# M3HQ register map
File version: 0.1
Registers are 32-bit, read-write, reset 0x0 unless marked. A register's access mark holds for its fields unless they carry their own. Offsets are from the block's base; [hi:lo] are bit positions; {n}, {i} and the like mark numbered series.

## PV
Base 0x400C1100
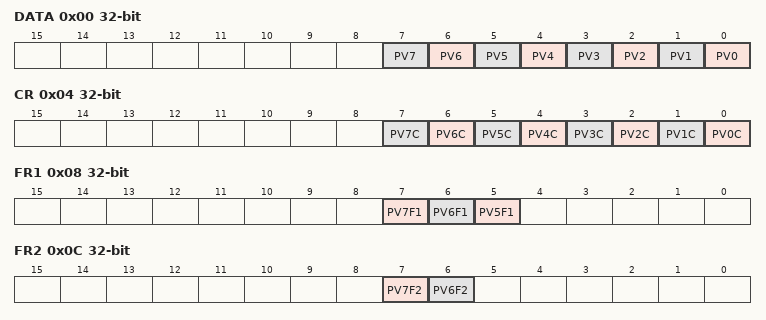
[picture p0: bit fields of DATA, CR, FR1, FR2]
0x00 DATA — PV Data Register
  [n] PV{n} (n=0..7)
0x04 CR — PV Control Register
  [n] PV{n}C (n=0..7)
0x08 FR1 — PV Function Register 1
  [7] PV7F1, [6] PV6F1, [5] PV5F1
0x0C FR2 — PV Function Register 2
  [7] PV7F2, [6] PV6F2
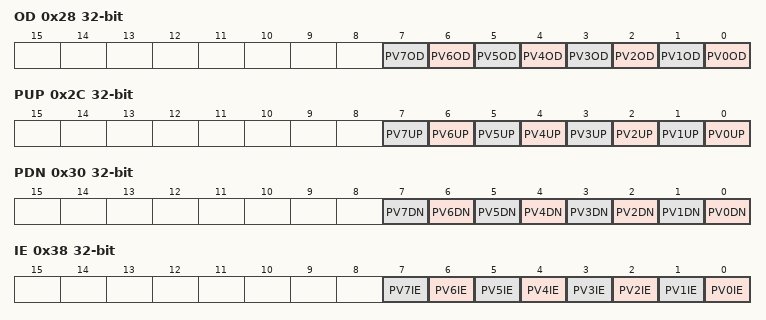
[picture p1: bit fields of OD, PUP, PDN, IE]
0x28 OD — PV Open Drain Control Register
  [n] PV{n}OD (n=0..7)
0x2C PUP — PV Pull-up Control Register
  [n] PV{n}UP (n=0..7)
0x30 PDN — PV Pull-Down Control Register
  [n] PV{n}DN (n=0..7)
0x38 IE — PV Input Enable Control Register
  [n] PV{n}IE (n=0..7)

## RTC
Base 0x400CC000
0x00 SECR 8-bit (reset mask 0x80) — RTC Sec setting register
  [6:0] SE
0x01 MINR 8-bit (reset mask 0x80) — RTC Min settging register
  [6:0] MI
0x02 HOURR 8-bit (reset mask 0xC0) — RTC Hour setting register
  [5:0] HO
0x04 DAYR 8-bit (reset mask 0xF8) — RTC Day setting register
  [2:0] WE
0x05 DATER 8-bit (reset mask 0xC0) — RTC Date setting register
  [5:0] DA
0x06 MONTHR_A 8-bit (reset mask 0xE0) — RTC Month settging register PAGE0
  [4:0] MO
0x06 MONTHR_B 8-bit (reset mask 0xFE) (RTC_MONTHR view) — RTC 24 hours _ 12 hours clock select register PAGE1
  [0] MO0
0x07 YEARR_A 8-bit reset not defined — RTC Year setting register PAGE0
  [7:0] YE
0x07 YEARR_B 8-bit (reset mask 0xFC) (RTC_YEARR view) — RTC Leap year register PAGE1
  [1:0] LEAP
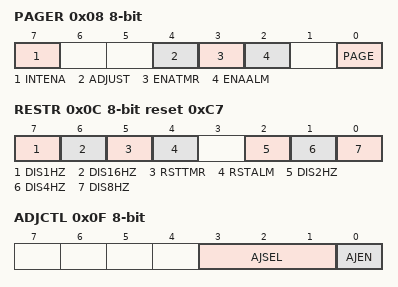
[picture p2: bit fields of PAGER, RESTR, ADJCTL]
0x08 PAGER 8-bit (reset mask 0xF3) — RTC Page register
  [7] INTENA, [4] ADJUST, [3] ENATMR, [2] ENAALM, [0] PAGE
0x0C RESTR 8-bit reset 0xC7 — RTC Reset register
  [7] DIS1HZ, [6] DIS16HZ, [5] RSTTMR, [4] RSTALM, [2] DIS2HZ, [1] DIS4HZ, [0] DIS8HZ
0x0E PROTECT 8-bit reset 0xC1 — RTC protect register
0x0F ADJCTL 8-bit (reset mask 0xF0) — RTC clock adjust control register
  [3:1] AJSEL, [0] AJEN
0x10 ADJDAT 8-bit reset not defined — RTC clock adjust data register
0x11 ADJSIGN 8-bit (reset mask 0xFE) — RTC clock adjust sign register
  [0] ADJSIGN

## RMC
Base 0x400E7000
0x00 EN — RMC Enable Register
  [0] RMCEN
0x04 REN — RMC Receive Enable Register
  [0] RMCREN
0x08 RBUF1 ro — RMC Receive Data Buffer Register 1
  [31:0] RMCRBUF
0x0C RBUF2 ro — RMC Receive Data Buffer Register 2
  [31:0] RMCRBUF
0x10 RBUF3 ro — RMC Receive Data Buffer Register 3
  [7:0] RMCRBUF
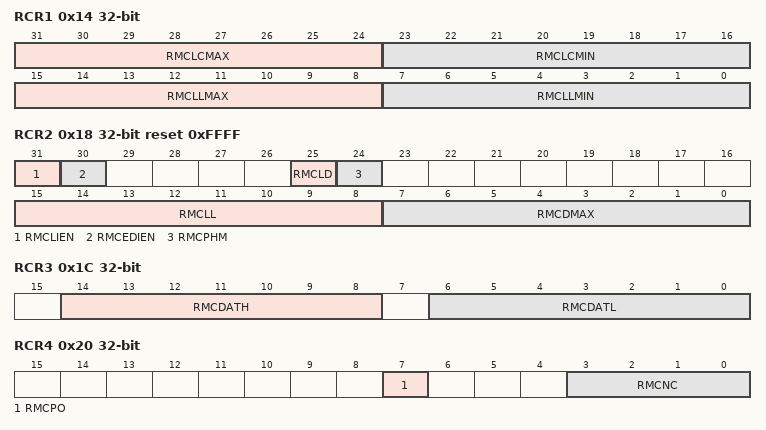
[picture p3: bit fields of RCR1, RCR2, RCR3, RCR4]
0x14 RCR1 — RMC Receive Control Register 1
  [31:24] RMCLCMAX, [23:16] RMCLCMIN, [15:8] RMCLLMAX, [7:0] RMCLLMIN
0x18 RCR2 reset 0xFFFF — RMC Receive Control Register 2
  [31] RMCLIEN, [30] RMCEDIEN, [25] RMCLD, [24] RMCPHM, [15:8] RMCLL, [7:0] RMCDMAX
0x1C RCR3 — RMC Receive Control Register 3
  [14:8] RMCDATH, [6:0] RMCDATL
0x20 RCR4 — RMC Receive Control Register 4
  [7] RMCPO, [3:0] RMCNC
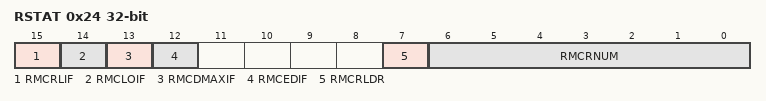
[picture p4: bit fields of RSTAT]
0x24 RSTAT ro — RMC Receive Status Register
  [15] RMCRLIF, [14] RMCLOIF, [13] RMCDMAXIF, [12] RMCEDIF, [7] RMCRLDR, [6:0] RMCRNUM
{0x24+4i} END{i} (i=1..3) — RMC Receive End Bit Number Register {i}
  [6:0] RMCEND{i}
0x34 FSSEL — RMC Frequency Selection Register
  [0] RMCCLK

## OFD
Base 0x400F1000
0x00 CR1 reset 0x6 — OFD Control Register 1
  [7:0] OFDWEN
0x04 CR2 — OFD Control Register 2
  [7:0] OFDEN
0x08 MN0 — OFD Lower Detection Frequency Setting Register0
  [11:0] OFDMN0
0x0C MN1 — OFD Lower Detection Frequency Setting Register1
  [11:0] OFDMN1
0x10 MX0 — OFD Higher Detection Frequency Setting Register0
  [11:0] OFDMX0
0x14 MX1 — OFD Higher Detection Frequency Setting Register1
  [11:0] OFDMX1
0x18 RST reset 0x1 — OFD Reset Enable Control Register
  [0] OFDRSTEN
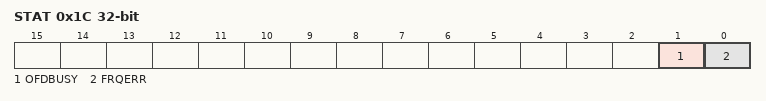
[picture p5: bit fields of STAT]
0x1C STAT ro — OFD Status Register
  [1] OFDBUSY, [0] FRQERR
0x20 MON reset 0x1 — OFD External high frequency oscillaion clock monitor register
  [0] OFDMON

## CG
Base 0x400F3000
0x00 PROTECT reset 0xC1 — CG Protect Register
  [7:0] PROTECT
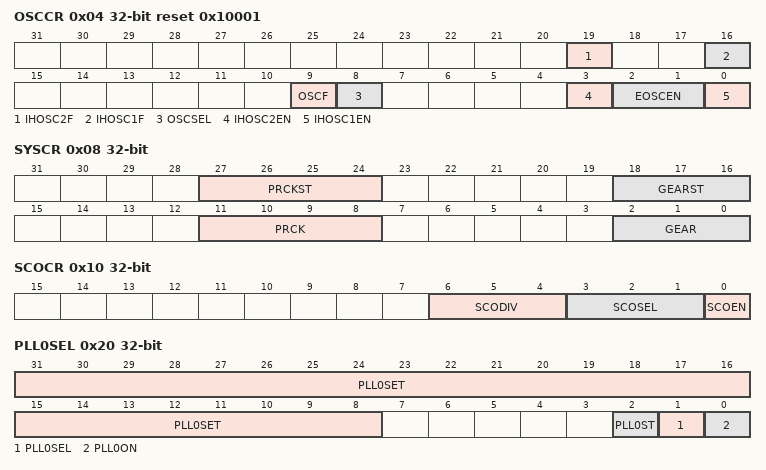
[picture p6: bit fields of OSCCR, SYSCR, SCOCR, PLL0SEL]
0x04 OSCCR reset 0x10001 — CG Oscillation Control Register
  [19] IHOSC2F ro, [16] IHOSC1F ro, [9] OSCF ro, [8] OSCSEL, [3] IHOSC2EN, [2:1] EOSCEN, [0] IHOSC1EN
0x08 SYSCR — CG System clock control register
  [27:24] PRCKST ro, [18:16] GEARST ro, [11:8] PRCK, [2:0] GEAR
0x0C STBYCR — CG Standby Control Register
  [1:0] STBY
0x10 SCOCR — CG SCOUT Control Register
  [6:4] SCODIV, [3:1] SCOSEL, [0] SCOEN
0x20 PLL0SEL — CG PLL select register for fsys
  [31:8] PLL0SET, [2] PLL0ST ro, [1] PLL0SEL, [0] PLL0ON
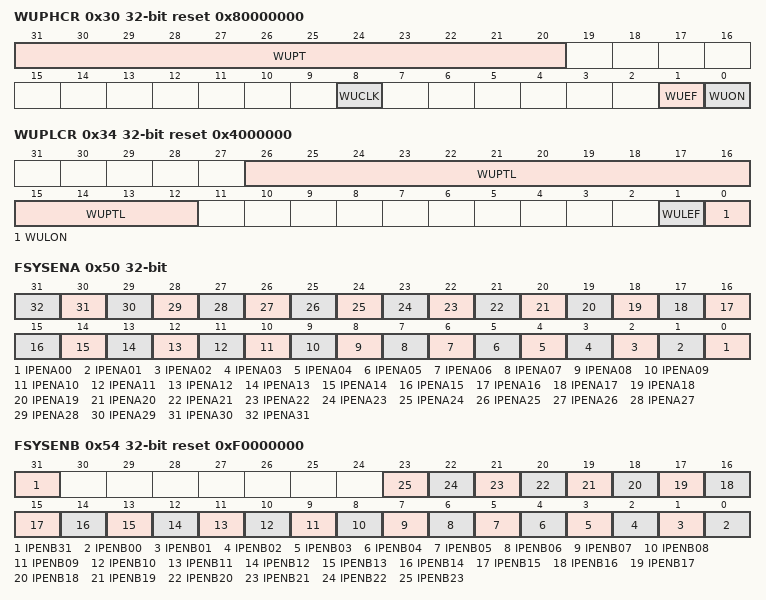
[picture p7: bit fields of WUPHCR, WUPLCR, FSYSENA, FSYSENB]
0x30 WUPHCR reset 0x80000000 — CG Warmup register for HOSC
  [31:20] WUPT, [8] WUCLK, [1] WUEF ro, [0] WUON wo
0x34 WUPLCR reset 0x4000000 — CG Low-speed oscillation warm-up register
  [26:12] WUPTL, [1] WULEF ro, [0] WULON wo
0x50 FSYSENA — CG output control register A for fsys clock
  [n] IPENA{n:02} (n=0..31)
0x54 FSYSENB reset 0xF0000000 — CG output control register B for fsys clock
  [31] IPENB31, [n] IPENB{n:02} (n=0..23)
0x58 FCEN — CG output control register for fc clock
  [7] FCIPEN07
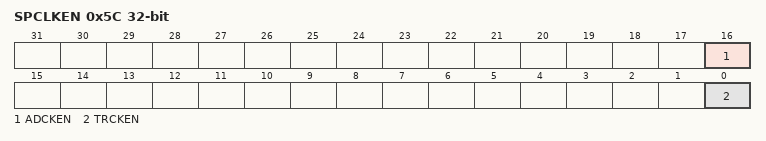
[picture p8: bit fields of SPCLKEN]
0x5C SPCLKEN — CG Output control register for ADC AND TRACE CLOCK
  [16] ADCKEN, [0] TRCKEN
